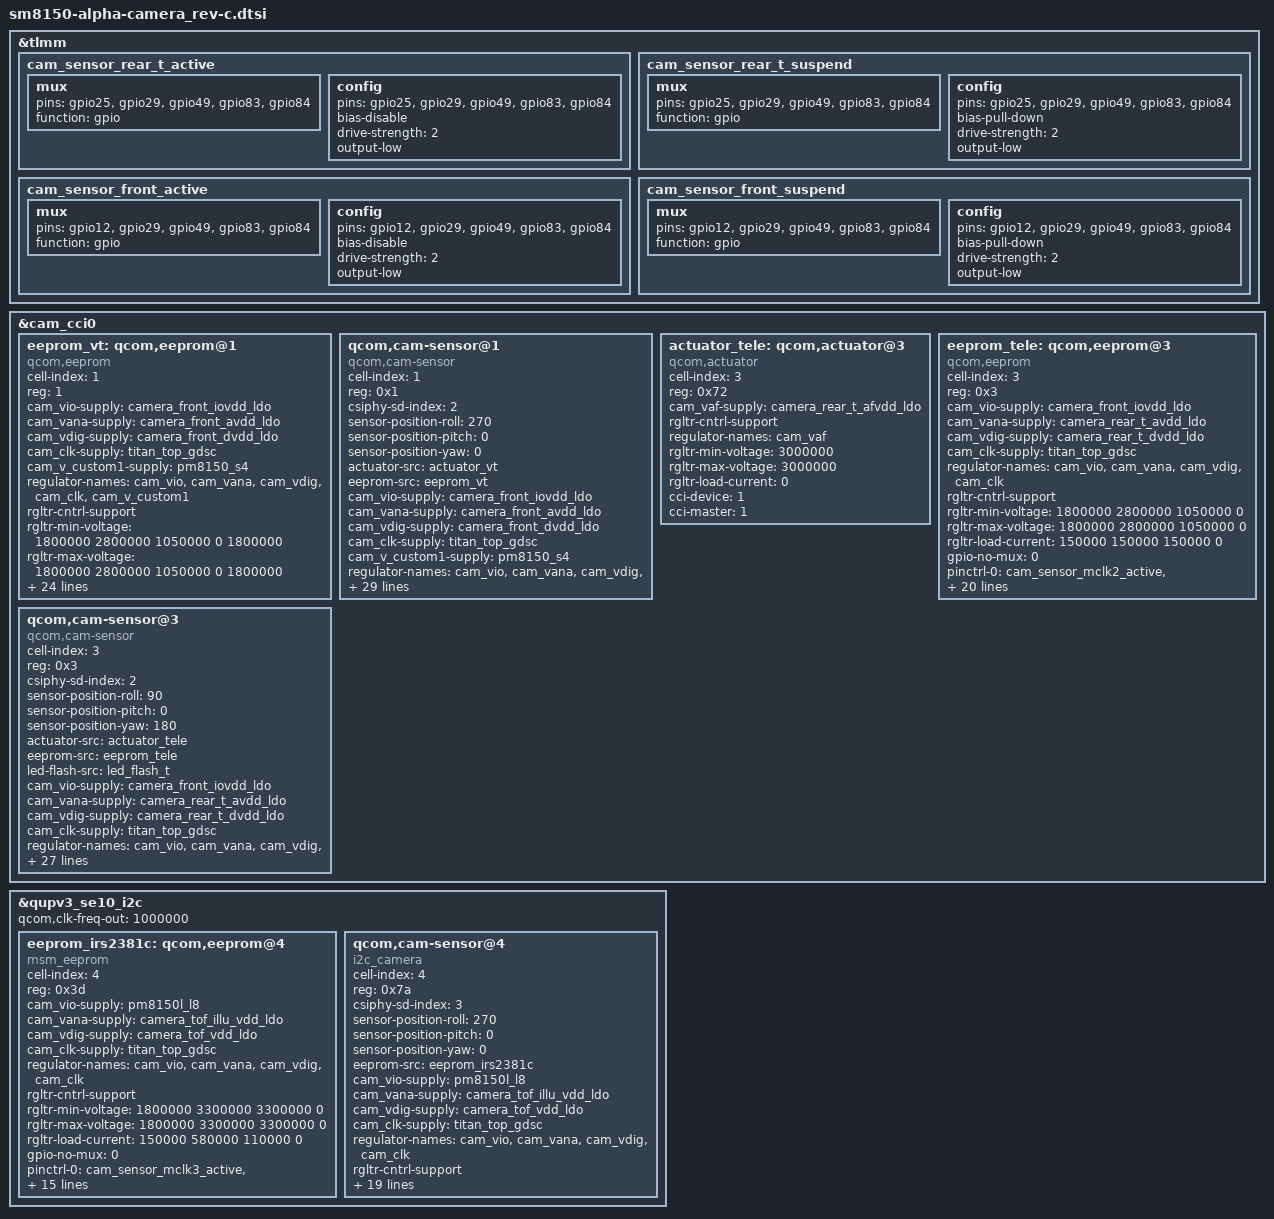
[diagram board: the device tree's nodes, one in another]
/*
 * Copyright (c) 2018, The Linux Foundation. All rights reserved.
 *
 * This program is free software; you can redistribute it and/or modify
 * it under the terms of the GNU General Public License version 2 and
 * only version 2 as published by the Free Software Foundation.
 *
 * This program is distributed in the hope that it will be useful,
 * but WITHOUT ANY WARRANTY; without even the implied warranty of
 * MERCHANTABILITY or FITNESS FOR A PARTICULAR PURPOSE.  See the
 * GNU General Public License for more details.
 */

#include "sm8150-alpha-camera_common.dtsi"

&tlmm {
	cam_sensor_rear_t_active: cam_sensor_rear_t_active {
		mux {
			pins = "gpio25", "gpio29", "gpio49", "gpio83", "gpio84";
			function = "gpio";
		};

		config {
			pins = "gpio25", "gpio29", "gpio49", "gpio83", "gpio84";
			bias-disable;
			drive-strength = <2>;
			output-low;
		};
	};

	cam_sensor_rear_t_suspend: cam_sensor_rear_t_suspend {
		mux {
			pins = "gpio25", "gpio29", "gpio49", "gpio83", "gpio84";
			function = "gpio";
		};

		config {
			pins = "gpio25", "gpio29", "gpio49", "gpio83", "gpio84";
			bias-pull-down;
			drive-strength = <2>;
			output-low;
		};
	};

	cam_sensor_front_active: cam_sensor_front_active {
		mux {
			pins = "gpio12", "gpio29", "gpio49", "gpio83", "gpio84";
			function = "gpio";
		};

		config {
			pins = "gpio12", "gpio29", "gpio49", "gpio83", "gpio84";
			bias-disable;
			drive-strength = <2>;
			output-low;
		};
	};

	cam_sensor_front_suspend: cam_sensor_front_suspend {
		mux {
			pins = "gpio12", "gpio29", "gpio49", "gpio83", "gpio84";
			function = "gpio";
		};

		config {
			pins = "gpio12", "gpio29", "gpio49", "gpio83", "gpio84";
			bias-pull-down;
			drive-strength = <2>;
			output-low;
		};
	};
};

&cam_cci0 {
	eeprom_vt: qcom,eeprom@1 {
		cell-index = <1>;
		reg = <1>;
		compatible = "qcom,eeprom";
		cam_vio-supply = <&camera_front_iovdd_ldo>;
		cam_vana-supply = <&camera_front_avdd_ldo>;
		cam_vdig-supply = <&camera_front_dvdd_ldo>;
		cam_clk-supply = <&titan_top_gdsc>;
		cam_v_custom1-supply = <&pm8150_s4>;
		regulator-names = "cam_vio", "cam_vana", "cam_vdig", "cam_clk", "cam_v_custom1";
		rgltr-cntrl-support;
		rgltr-min-voltage = <1800000 2800000 1050000 0 1800000>;
		rgltr-max-voltage = <1800000 2800000 1050000 0 1800000>;
		rgltr-load-current = <150000 150000 150000 0 3500000>;
		gpio-no-mux = <0>;
		pinctrl-names = "cam_default", "cam_suspend";
		pinctrl-0 = <&cam_sensor_mclk2_active
				 &cam_sensor_front_active>;
		pinctrl-1 = <&cam_sensor_mclk2_suspend
				 &cam_sensor_front_suspend>;
		gpios = <&tlmm 15 0>,
			<&tlmm 12 0>,
			<&tlmm 49 0>,
			<&tlmm 29 0>,
			<&tlmm 83 0>;
		gpio-reset = <1>;
		gpio-standby = <2>;
		gpio-custom1 = <3>;
		gpio-custom2 = <4>;
		gpio-req-tbl-num = <0 1 2 3 4>;
		gpio-req-tbl-flags = <1 0 0 0 0>;
		gpio-req-tbl-label = "VT_MCLK",
					"VT_RESET",
					"VT_MIPI_SW_OE_N",
					"VT_MIPI_SEL",
					"VT_MCLK_REQ_1";
		sensor-position = <0>;
		sensor-mode = <0>;
		cci-device = <1>;
		cci-master = <0>;
		status = "ok";
		clocks = <&clock_camcc CAM_CC_MCLK2_CLK>;
		clock-names = "cam_clk";
		clock-cntl-level = "turbo";
		clock-rates = <24000000>;
	};

	qcom,cam-sensor@1 {
		cell-index = <1>;
		compatible = "qcom,cam-sensor";
		reg = <0x1>;
		csiphy-sd-index = <2>;
		sensor-position-roll = <270>;
		sensor-position-pitch = <0>;
		sensor-position-yaw = <0>;
		actuator-src = <&actuator_vt>;
		eeprom-src = <&eeprom_vt>;
		cam_vio-supply = <&camera_front_iovdd_ldo>;
		cam_vana-supply = <&camera_front_avdd_ldo>;
		cam_vdig-supply = <&camera_front_dvdd_ldo>;
		cam_clk-supply = <&titan_top_gdsc>;
		cam_v_custom1-supply = <&pm8150_s4>;
		regulator-names = "cam_vio", "cam_vana", "cam_vdig", "cam_clk", "cam_v_custom1";
		rgltr-cntrl-support;
		rgltr-min-voltage = <1800000 2800000 1050000 0 1800000>;
		rgltr-max-voltage = <1800000 2800000 1050000 0 1800000>;
		rgltr-load-current = <150000 150000 150000 0 3500000>;
		gpio-no-mux = <0>;
		pinctrl-names = "cam_default", "cam_suspend";
		pinctrl-0 = <&cam_sensor_mclk2_active
				 &cam_sensor_front_active>;
		pinctrl-1 = <&cam_sensor_mclk2_suspend
				 &cam_sensor_front_suspend>;
		gpios = <&tlmm 15 0>,
			<&tlmm 12 0>,
			<&tlmm 49 0>,
			<&tlmm 29 0>,
			<&tlmm 83 0>;
		gpio-reset = <1>;
		gpio-standby = <2>;
		gpio-custom1 = <3>;
		gpio-custom2 = <4>;
		gpio-req-tbl-num = <0 1 2 3 4>;
		gpio-req-tbl-flags = <1 0 0 0 0>;
		gpio-req-tbl-label = "VT_MCLK",
					"VT_RESET",
					"VT_MIPI_SW_OE_N",
					"VT_MIPI_SEL",
					"VT_MCLK_REQ_1";
		sensor-mode = <0>;
		cci-device = <1>;
		cci-master = <0>;
		status = "ok";
		clocks = <&clock_camcc CAM_CC_MCLK2_CLK>;
		clock-names = "cam_clk";
		clock-cntl-level = "turbo";
		clock-rates = <24000000>;
	};

	actuator_tele: qcom,actuator@3 {
		cell-index = <3>;
		reg = <0x72>;
		compatible = "qcom,actuator";
		cam_vaf-supply = <&camera_rear_t_afvdd_ldo>;
		rgltr-cntrl-support;
		regulator-names = "cam_vaf";
		rgltr-min-voltage = <3000000>;
		rgltr-max-voltage = <3000000>;
		rgltr-load-current = <0>;
		status = "ok";
		cci-device = <1>;
		cci-master = <1>;
	};

	eeprom_tele: qcom,eeprom@3 {
		cell-index = <3>;
		reg = <0x3>;
		compatible = "qcom,eeprom";
		cam_vio-supply = <&camera_front_iovdd_ldo>;
		cam_vana-supply = <&camera_rear_t_avdd_ldo>;
		cam_vdig-supply = <&camera_rear_t_dvdd_ldo>;
		cam_clk-supply = <&titan_top_gdsc>;
		regulator-names = "cam_vio", "cam_vana", "cam_vdig", "cam_clk";
		rgltr-cntrl-support;
		rgltr-min-voltage = <1800000 2800000 1050000 0>;
		rgltr-max-voltage = <1800000 2800000 1050000 0>;
		rgltr-load-current = <150000 150000 150000 0>;
		gpio-no-mux = <0>;
		pinctrl-names = "cam_default", "cam_suspend";
		pinctrl-0 = <&cam_sensor_mclk2_active
				 &cam_sensor_rear_t_active>;
		pinctrl-1 = <&cam_sensor_mclk2_suspend
				 &cam_sensor_rear_t_suspend>;
		gpios = <&tlmm 15 0>,
			<&tlmm 25 0>,
			<&tlmm 49 0>,
			<&tlmm 29 0>,
			<&tlmm 84 0>;
		gpio-reset = <1>;
		gpio-standby = <2>;
		gpio-custom1 = <3>;
		gpio-custom2 = <4>;
		gpio-req-tbl-num = <0 1 2 3 4>;
		gpio-req-tbl-flags = <1 0 0 0 0>;
		gpio-req-tbl-label = "TELE_MCLK",
					"TELE_RESET",
					"TELE_MIPI_SW_OE_N",
					"TELE_MIPI_SEL",
					"TELE_MCLK_REQ_1";
		sensor-mode = <0>;
		cci-device = <1>;
		cci-master = <1>;
		status = "ok";
		clocks = <&clock_camcc CAM_CC_MCLK2_CLK>;
		clock-names = "cam_clk";
		clock-cntl-level = "turbo";
		clock-rates = <24000000>;
	};

	qcom,cam-sensor@3 {
		cell-index = <3>;
		compatible = "qcom,cam-sensor";
		reg = <0x3>;
		csiphy-sd-index = <2>;
		sensor-position-roll = <90>;
		sensor-position-pitch = <0>;
		sensor-position-yaw = <180>;
		actuator-src = <&actuator_tele>;
		eeprom-src = <&eeprom_tele>;
		led-flash-src = <&led_flash_t>;
		cam_vio-supply = <&camera_front_iovdd_ldo>;
		cam_vana-supply = <&camera_rear_t_avdd_ldo>;
		cam_vdig-supply = <&camera_rear_t_dvdd_ldo>;
		cam_clk-supply = <&titan_top_gdsc>;
		regulator-names = "cam_vio", "cam_vana", "cam_vdig", "cam_clk";
		rgltr-cntrl-support;
		rgltr-min-voltage = <1800000 2800000 1050000 0>;
		rgltr-max-voltage = <1800000 2800000 1050000 0>;
		rgltr-load-current = <150000 150000 150000 0>;
		gpio-no-mux = <0>;
		pinctrl-names = "cam_default", "cam_suspend";
		pinctrl-0 = <&cam_sensor_mclk2_active
				 &cam_sensor_rear_t_active>;
		pinctrl-1 = <&cam_sensor_mclk2_suspend
				 &cam_sensor_rear_t_suspend>;
		gpios = <&tlmm 15 0>,
			<&tlmm 25 0>,
			<&tlmm 49 0>,
			<&tlmm 29 0>,
			<&tlmm 84 0>;
		gpio-reset = <1>;
		gpio-standby = <2>;
		gpio-custom1 = <3>;
		gpio-custom2 = <4>;
		gpio-req-tbl-num = <0 1 2 3 4>;
		gpio-req-tbl-flags = <1 0 0 0 0>;
		gpio-req-tbl-label = "TELE_MCLK",
					"TELE_RESET",
					"TELE_MIPI_SW_OE_N",
					"TELE_MIPI_SEL",
					"TELE_MCLK_REQ_1";
		sensor-mode = <0>;
		cci-device = <1>;
		cci-master = <1>;
		status = "ok";
		clocks = <&clock_camcc CAM_CC_MCLK2_CLK>;
		clock-names = "cam_clk";
		clock-cntl-level = "turbo";
		clock-rates = <24000000>;
	};
};

&qupv3_se10_i2c {
	status = "ok";
	qcom,clk-freq-out = <1000000>;

	eeprom_irs2381c: qcom,eeprom@4 {
		cell-index = <4>;
		reg = <0x3d>;
		compatible = "msm_eeprom";
		cam_vio-supply = <&pm8150l_l8>;
		cam_vana-supply = <&camera_tof_illu_vdd_ldo>;
		cam_vdig-supply = <&camera_tof_vdd_ldo>;
		cam_clk-supply = <&titan_top_gdsc>;
		regulator-names = "cam_vio", "cam_vana", "cam_vdig",
			"cam_clk";
		rgltr-cntrl-support;
		rgltr-min-voltage = <1800000 3300000 3300000 0>;
		rgltr-max-voltage = <1800000 3300000 3300000 0>;
		rgltr-load-current = <150000 580000 110000 0>;
		gpio-no-mux = <0>;
		pinctrl-names = "cam_default", "cam_suspend";
		pinctrl-0 = <&cam_sensor_mclk3_active
				 &cam_sensor_tof_active>;
		pinctrl-1 = <&cam_sensor_mclk3_suspend
				 &cam_sensor_tof_suspend>;
		gpios = <&tlmm 16 0>,
			<&tlmm 23 0>;
		gpio-reset = <1>;
		gpio-req-tbl-num = <0 1>;
		gpio-req-tbl-flags = <1 0>;
		gpio-req-tbl-label = "CAMIF_MCLK3",
					"CAM_RESET3";
		sensor-position = <0>;
		sensor-mode = <0>;
		cci-device = <1>;
		cci-master = <1>;
		status = "ok";
		clocks = <&clock_camcc CAM_CC_MCLK3_CLK>;
		clock-names = "cam_clk";
		clock-cntl-level = "turbo";
		clock-rates = <24000000>;
	};

	qcom,cam-sensor@4 {
		cell-index = <4>;
		compatible = "i2c_camera";
		reg = <0x7a>;
		csiphy-sd-index = <3>;
		sensor-position-roll = <270>;
		sensor-position-pitch = <0>;
		sensor-position-yaw = <0>;
		eeprom-src = <&eeprom_irs2381c>;
		cam_vio-supply = <&pm8150l_l8>;
		cam_vana-supply = <&camera_tof_illu_vdd_ldo>;
		cam_vdig-supply = <&camera_tof_vdd_ldo>;
		cam_clk-supply = <&titan_top_gdsc>;
		regulator-names = "cam_vio", "cam_vana", "cam_vdig",
			"cam_clk";
		rgltr-cntrl-support;
		rgltr-min-voltage = <1800000 3300000 3300000 0>;
		rgltr-max-voltage = <1800000 3300000 3300000 0>;
		rgltr-load-current = <150000 580000 110000 0>;
		gpio-no-mux = <0>;
		pinctrl-names = "cam_default", "cam_suspend";
		pinctrl-0 = <&cam_sensor_mclk3_active
				 &cam_sensor_tof_active>;
		pinctrl-1 = <&cam_sensor_mclk3_suspend
				 &cam_sensor_tof_suspend>;
		gpios = <&tlmm 16 0>,
			<&tlmm 23 0>;
		gpio-reset = <1>;
		gpio-req-tbl-num = <0 1>;
		gpio-req-tbl-flags = <1 0>;
		gpio-req-tbl-label = "CAMIF_MCLK3",
					"CAM_RESET3";
		sensor-mode = <0>;
		cci-device = <1>;
		cci-master = <1>;
		status = "ok";
		clocks = <&clock_camcc CAM_CC_MCLK3_CLK>;
		clock-names = "cam_clk";
		clock-cntl-level = "turbo";
		clock-rates = <24000000>;
	};
};
